# ESP32-P4-LP register map
Vendor: ESPRESSIF SYSTEMS (SHANGHAI) CO., LTD.; Series: ESP32 P-Series; File version: 3
CPU: RV32IMAC r0p0, little endian, no MPU, no FPU, 0 interrupt priority bits
Address unit: 32 bits
Registers are 32-bit, read-write, reset 0x0 unless marked. A register's access mark holds for its fields unless they carry their own. Offsets are from the block's base; [hi:lo] are bit positions; {n}, {i} and the like mark numbered series.

## LP_SPI
Base 0x50123000
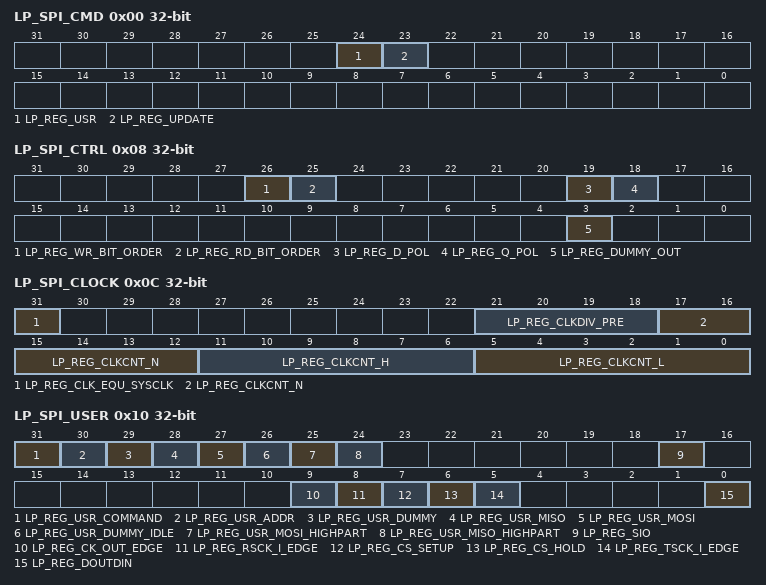
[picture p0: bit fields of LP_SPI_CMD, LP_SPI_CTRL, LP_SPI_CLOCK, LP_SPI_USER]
0x00 LP_SPI_CMD access per field — Command control register
  [24] LP_REG_USR rw — User define command enable. An operation will be triggered when the bit is set. The bit will be cleared once the operation done.1: enable 0: disable. Can not be changed by CONF_buf.
  [23] LP_REG_UPDATE wo — Set this bit to synchronize SPI registers from APB clock domain into SPI module clock domain, which is only used in SPI master mode.
0x04 LP_SPI_ADDR — Address value register
  [31:0] LP_REG_USR_ADDR_VALUE — Address to slave. Can be configured in CONF state.
0x08 LP_SPI_CTRL — SPI control register
  [26] LP_REG_WR_BIT_ORDER — In command address write-data (MOSI) phases 1: LSB firs 0: MSB first. Can be configured in CONF state.
  [25] LP_REG_RD_BIT_ORDER — In read-data (MISO) phase 1: LSB first 0: MSB first. Can be configured in CONF state.
  [19] LP_REG_D_POL — The bit is used to set MOSI line polarity, 1: high 0, low. Can be configured in CONF state.
  [18] LP_REG_Q_POL — The bit is used to set MISO line polarity, 1: high 0, low. Can be configured in CONF state.
  [3] LP_REG_DUMMY_OUT — In the dummy phase the signal level of spi is output by the spi controller. Can be configured in CONF state.
0x0C LP_SPI_CLOCK — SPI clock control register
  [31] LP_REG_CLK_EQU_SYSCLK — In the master mode 1: spi_clk is equal to system 0: spi_clk is divided from system clock. Can be configured in CONF state.
  [21:18] LP_REG_CLKDIV_PRE — In the master mode it is pre-divider of spi_clk. Can be configured in CONF state.
  [17:12] LP_REG_CLKCNT_N — In the master mode it is the divider of spi_clk. So spi_clk frequency is system/(spi_clkdiv_pre+1)/(spi_clkcnt_N+1). Can be configured in CONF state.
  [11:6] LP_REG_CLKCNT_H — In the master mode it must be floor((spi_clkcnt_N+1)/2-1). In the slave mode it must be 0. Can be configured in CONF state.
  [5:0] LP_REG_CLKCNT_L — In the master mode it must be equal to spi_clkcnt_N. In the slave mode it must be 0. Can be configured in CONF state.
0x10 LP_SPI_USER — SPI USER control register
  [31] LP_REG_USR_COMMAND — This bit enable the command phase of an operation. Can be configured in CONF state.
  [30] LP_REG_USR_ADDR — This bit enable the address phase of an operation. Can be configured in CONF state.
  [29] LP_REG_USR_DUMMY — This bit enable the dummy phase of an operation. Can be configured in CONF state.
  [28] LP_REG_USR_MISO — This bit enable the read-data phase of an operation. Can be configured in CONF state.
  [27] LP_REG_USR_MOSI — This bit enable the write-data phase of an operation. Can be configured in CONF state.
  [26] LP_REG_USR_DUMMY_IDLE — spi clock is disable in dummy phase when the bit is enable. Can be configured in CONF state.
  [25] LP_REG_USR_MOSI_HIGHPART — write-data phase only access to high-part of the buffer spi_w8~spi_w15. 1: enable 0: disable. Can be configured in CONF state.
  [24] LP_REG_USR_MISO_HIGHPART — read-data phase only access to high-part of the buffer spi_w8~spi_w15. 1: enable 0: disable. Can be configured in CONF state.
  [17] LP_REG_SIO — Set the bit to enable 3-line half duplex communication mosi and miso signals share the same pin. 1: enable 0: disable. Can be configured in CONF state.
  [9] LP_REG_CK_OUT_EDGE — the bit combined with spi_mosi_delay_mode bits to set mosi signal delay mode. Can be configured in CONF state.
  [8] LP_REG_RSCK_I_EDGE — In the slave mode, this bit can be used to change the polarity of rsck. 0: rsck = !spi_ck_i. 1:rsck = spi_ck_i.
  [7] LP_REG_CS_SETUP — spi cs is enable when spi is in prepare phase. 1: enable 0: disable. Can be configured in CONF state.
  [6] LP_REG_CS_HOLD — spi cs keep low when spi is in done phase. 1: enable 0: disable. Can be configured in CONF state.
  [5] LP_REG_TSCK_I_EDGE — In the slave mode, this bit can be used to change the polarity of tsck. 0: tsck = spi_ck_i. 1:tsck = !spi_ck_i.
  [0] LP_REG_DOUTDIN — Set the bit to enable full duplex communication. 1: enable 0: disable. Can be configured in CONF state.
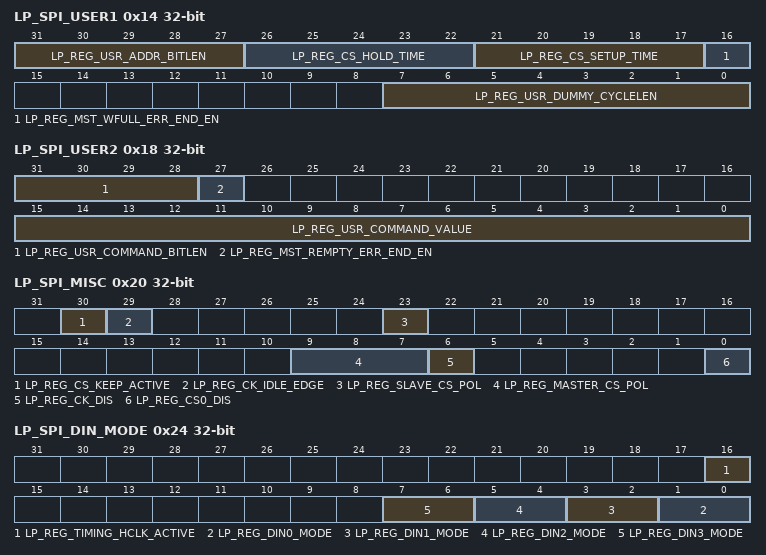
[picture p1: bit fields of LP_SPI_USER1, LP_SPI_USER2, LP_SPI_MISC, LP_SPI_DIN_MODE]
0x14 LP_SPI_USER1 — SPI USER control register 1
  [31:27] LP_REG_USR_ADDR_BITLEN — The length in bits of address phase. The register value shall be (bit_num-1). Can be configured in CONF state.
  [26:22] LP_REG_CS_HOLD_TIME — delay cycles of cs pin by spi clock this bits are combined with spi_cs_hold bit. Can be configured in CONF state.
  [21:17] LP_REG_CS_SETUP_TIME — (cycles+1) of prepare phase by spi clock this bits are combined with spi_cs_setup bit. Can be configured in CONF state.
  [16] LP_REG_MST_WFULL_ERR_END_EN — 1: SPI transfer is ended when SPI RX AFIFO wfull error is valid in GP-SPI master FD/HD-mode. 0: SPI transfer is not ended when SPI RX AFIFO wfull error is valid in GP-SPI master FD/HD-mode.
  [7:0] LP_REG_USR_DUMMY_CYCLELEN — The length in spi_clk cycles of dummy phase. The register value shall be (cycle_num-1). Can be configured in CONF state.
0x18 LP_SPI_USER2 — SPI USER control register 2
  [31:28] LP_REG_USR_COMMAND_BITLEN — The length in bits of command phase. The register value shall be (bit_num-1). Can be configured in CONF state.
  [27] LP_REG_MST_REMPTY_ERR_END_EN — 1: SPI transfer is ended when SPI TX AFIFO read empty error is valid in GP-SPI master FD/HD-mode. 0: SPI transfer is not ended when SPI TX AFIFO read empty error is valid in GP-SPI master FD/HD-mode.
  [15:0] LP_REG_USR_COMMAND_VALUE — The value of command. Can be configured in CONF state.
0x1C LP_SPI_MS_DLEN — SPI data bit length control register
  [17:0] LP_REG_MS_DATA_BITLEN — The value of these bits is the configured SPI transmission data bit length in master mode DMA controlled transfer or CPU controlled transfer. The value is also the configured bit length in slave mode DMA RX controlled transfer. The register value shall be (bit_num-1). Can be configured in CONF state.
0x20 LP_SPI_MISC — SPI misc register
  [30] LP_REG_CS_KEEP_ACTIVE — spi cs line keep low when the bit is set. Can be configured in CONF state.
  [29] LP_REG_CK_IDLE_EDGE — 1: spi clk line is high when idle 0: spi clk line is low when idle. Can be configured in CONF state.
  [23] LP_REG_SLAVE_CS_POL — spi slave input cs polarity select. 1: inv 0: not change. Can be configured in CONF state.
  [9:7] LP_REG_MASTER_CS_POL — In the master mode the bits are the polarity of spi cs line, the value is equivalent to spi_cs ^ spi_master_cs_pol. Can be configured in CONF state.
  [6] LP_REG_CK_DIS — 1: spi clk out disable, 0: spi clk out enable. Can be configured in CONF state.
  [0] LP_REG_CS0_DIS — SPI CS$n pin enable, 1: disable CS$n, 0: spi_cs$n signal is from/to CS$n pin. Can be configured in CONF state.
0x24 LP_SPI_DIN_MODE — SPI input delay mode configuration
  [16] LP_REG_TIMING_HCLK_ACTIVE — 1:enable hclk in SPI input timing module. 0: disable it. Can be configured in CONF state.
  [2n+1:2n] LP_REG_DIN{n}_MODE (n=0..3) — the input signals are delayed by SPI module clock cycles, 0: input without delayed, 1: input with the posedge of clk_apb,2 input with the negedge of clk_apb, 3: input with the spi_clk. Can be configured in CONF state.
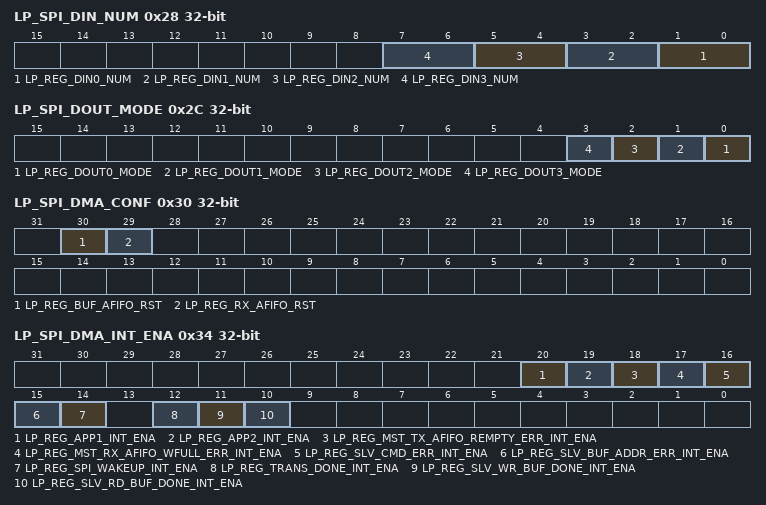
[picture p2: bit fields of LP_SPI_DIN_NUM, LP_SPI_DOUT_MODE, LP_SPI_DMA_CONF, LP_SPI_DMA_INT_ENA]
0x28 LP_SPI_DIN_NUM — SPI input delay number configuration
  [2n+1:2n] LP_REG_DIN{n}_NUM (n=0..3) — the input signals are delayed by SPI module clock cycles, 0: delayed by 1 cycle, 1: delayed by 2 cycles,... Can be configured in CONF state.
0x2C LP_SPI_DOUT_MODE — SPI output delay mode configuration
  [n] LP_REG_DOUT{n}_MODE (n=0..3) — The output signal $n is delayed by the SPI module clock, 0: output without delayed, 1: output delay for a SPI module clock cycle at its negative edge. Can be configured in CONF state.
0x30 LP_SPI_DMA_CONF wo — SPI DMA control register
  [30] LP_REG_BUF_AFIFO_RST — Set this bit to reset BUF TX AFIFO, which is used send data out in SPI slave CPU controlled mode transfer and master mode transfer.
  [29] LP_REG_RX_AFIFO_RST — Set this bit to reset RX AFIFO, which is used to receive data in SPI master and slave mode transfer.
0x34 LP_SPI_DMA_INT_ENA — SPI DMA interrupt enable register
  [20] LP_REG_APP1_INT_ENA — The enable bit for SPI_APP1_INT interrupt.
  [19] LP_REG_APP2_INT_ENA — The enable bit for SPI_APP2_INT interrupt.
  [18] LP_REG_MST_TX_AFIFO_REMPTY_ERR_INT_ENA — The enable bit for SPI_MST_TX_AFIFO_REMPTY_ERR_INT interrupt.
  [17] LP_REG_MST_RX_AFIFO_WFULL_ERR_INT_ENA — The enable bit for SPI_MST_RX_AFIFO_WFULL_ERR_INT interrupt.
  [16] LP_REG_SLV_CMD_ERR_INT_ENA — The enable bit for SPI_SLV_CMD_ERR_INT interrupt.
  [15] LP_REG_SLV_BUF_ADDR_ERR_INT_ENA — The enable bit for SPI_SLV_BUF_ADDR_ERR_INT interrupt.
  [14] LP_REG_SPI_WAKEUP_INT_ENA — The enable bit for SPI_WAKEUP_INT interrupt
  [12] LP_REG_TRANS_DONE_INT_ENA — The enable bit for SPI_TRANS_DONE_INT interrupt.
  [11] LP_REG_SLV_WR_BUF_DONE_INT_ENA — The enable bit for SPI_SLV_WR_BUF_DONE_INT interrupt.
  [10] LP_REG_SLV_RD_BUF_DONE_INT_ENA — The enable bit for SPI_SLV_RD_BUF_DONE_INT interrupt.
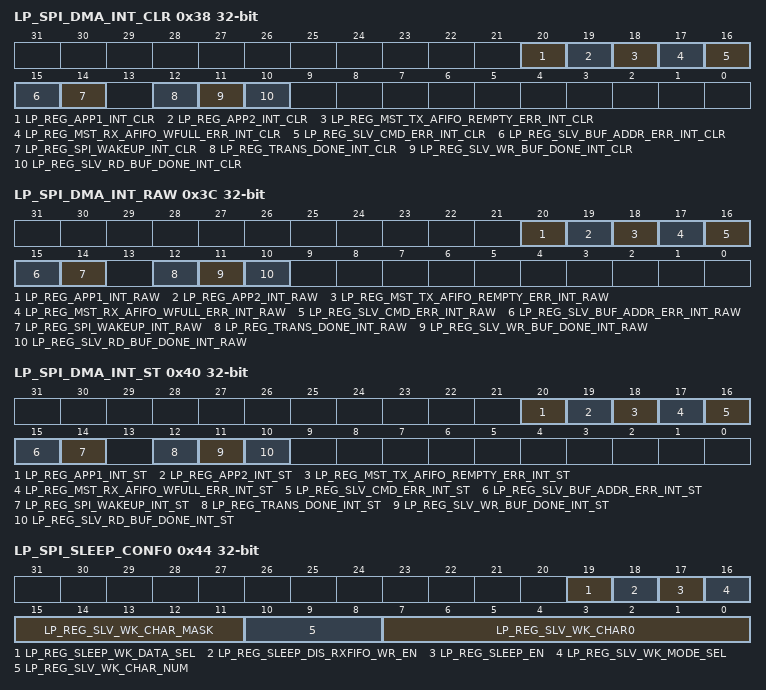
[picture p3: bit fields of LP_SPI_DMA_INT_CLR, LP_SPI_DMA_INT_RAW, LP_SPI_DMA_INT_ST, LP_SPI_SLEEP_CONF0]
0x38 LP_SPI_DMA_INT_CLR wo — SPI DMA interrupt clear register
  [20] LP_REG_APP1_INT_CLR — The clear bit for SPI_APP1_INT interrupt.
  [19] LP_REG_APP2_INT_CLR — The clear bit for SPI_APP2_INT interrupt.
  [18] LP_REG_MST_TX_AFIFO_REMPTY_ERR_INT_CLR — The clear bit for SPI_MST_TX_AFIFO_REMPTY_ERR_INT interrupt.
  [17] LP_REG_MST_RX_AFIFO_WFULL_ERR_INT_CLR — The clear bit for SPI_MST_RX_AFIFO_WFULL_ERR_INT interrupt.
  [16] LP_REG_SLV_CMD_ERR_INT_CLR — The clear bit for SPI_SLV_CMD_ERR_INT interrupt.
  [15] LP_REG_SLV_BUF_ADDR_ERR_INT_CLR — The clear bit for SPI_SLV_BUF_ADDR_ERR_INT interrupt.
  [14] LP_REG_SPI_WAKEUP_INT_CLR — The clear bit for SPI_WAKEUP_INT interrupt
  [12] LP_REG_TRANS_DONE_INT_CLR — The clear bit for SPI_TRANS_DONE_INT interrupt.
  [11] LP_REG_SLV_WR_BUF_DONE_INT_CLR — The clear bit for SPI_SLV_WR_BUF_DONE_INT interrupt.
  [10] LP_REG_SLV_RD_BUF_DONE_INT_CLR — The clear bit for SPI_SLV_RD_BUF_DONE_INT interrupt.
0x3C LP_SPI_DMA_INT_RAW — SPI DMA interrupt raw register
  [20] LP_REG_APP1_INT_RAW — The raw bit for SPI_APP1_INT interrupt. The value is only controlled by application.
  [19] LP_REG_APP2_INT_RAW — The raw bit for SPI_APP2_INT interrupt. The value is only controlled by application.
  [18] LP_REG_MST_TX_AFIFO_REMPTY_ERR_INT_RAW — The raw bit for SPI_MST_TX_AFIFO_REMPTY_ERR_INT interrupt. 1: There is a TX BUF AFIFO read-empty error when SPI outputs data in master mode. 0: Others.
  [17] LP_REG_MST_RX_AFIFO_WFULL_ERR_INT_RAW — The raw bit for SPI_MST_RX_AFIFO_WFULL_ERR_INT interrupt. 1: There is a RX AFIFO write-full error when SPI inputs data in master mode. 0: Others.
  [16] LP_REG_SLV_CMD_ERR_INT_RAW — The raw bit for SPI_SLV_CMD_ERR_INT interrupt. 1: The slave command value in the current SPI slave HD mode transmission is not supported. 0: Others.
  [15] LP_REG_SLV_BUF_ADDR_ERR_INT_RAW — The raw bit for SPI_SLV_BUF_ADDR_ERR_INT interrupt. 1: The accessing data address of the current SPI slave mode CPU controlled FD, Wr_BUF or Rd_BUF transmission is bigger than 63. 0: Others.
  [14] LP_REG_SPI_WAKEUP_INT_RAW — The raw bit for SPI_SPI_WAKEUP_INT interrupt. 1: There is a wake up signal when low power mode. 0: Others.
  [12] LP_REG_TRANS_DONE_INT_RAW — The raw bit for SPI_TRANS_DONE_INT interrupt. 1: SPI master mode transmission is ended. 0: others.
  [11] LP_REG_SLV_WR_BUF_DONE_INT_RAW — The raw bit for SPI_SLV_WR_BUF_DONE_INT interrupt. 1: SPI slave mode Wr_BUF transmission is ended. 0: Others.
  [10] LP_REG_SLV_RD_BUF_DONE_INT_RAW — The raw bit for SPI_SLV_RD_BUF_DONE_INT interrupt. 1: SPI slave mode Rd_BUF transmission is ended. 0: Others.
0x40 LP_SPI_DMA_INT_ST ro — SPI DMA interrupt status register
  [20] LP_REG_APP1_INT_ST — The status bit for SPI_APP1_INT interrupt.
  [19] LP_REG_APP2_INT_ST — The status bit for SPI_APP2_INT interrupt.
  [18] LP_REG_MST_TX_AFIFO_REMPTY_ERR_INT_ST — The status bit for SPI_MST_TX_AFIFO_REMPTY_ERR_INT interrupt.
  [17] LP_REG_MST_RX_AFIFO_WFULL_ERR_INT_ST — The status bit for SPI_MST_RX_AFIFO_WFULL_ERR_INT interrupt.
  [16] LP_REG_SLV_CMD_ERR_INT_ST — The status bit for SPI_SLV_CMD_ERR_INT interrupt.
  [15] LP_REG_SLV_BUF_ADDR_ERR_INT_ST — The status bit for SPI_SLV_BUF_ADDR_ERR_INT interrupt.
  [14] LP_REG_SPI_WAKEUP_INT_ST — reserved
  [12] LP_REG_TRANS_DONE_INT_ST — The status bit for SPI_TRANS_DONE_INT interrupt.
  [11] LP_REG_SLV_WR_BUF_DONE_INT_ST — The status bit for SPI_SLV_WR_BUF_DONE_INT interrupt.
  [10] LP_REG_SLV_RD_BUF_DONE_INT_ST — The status bit for SPI_SLV_RD_BUF_DONE_INT interrupt.
0x44 LP_SPI_SLEEP_CONF0
  [19] LP_REG_SLEEP_WK_DATA_SEL, [18] LP_REG_SLEEP_DIS_RXFIFO_WR_EN, [17] LP_REG_SLEEP_EN, [16] LP_REG_SLV_WK_MODE_SEL, [15:11] LP_REG_SLV_WK_CHAR_MASK, [10:8] LP_REG_SLV_WK_CHAR_NUM, [7:0] LP_REG_SLV_WK_CHAR0
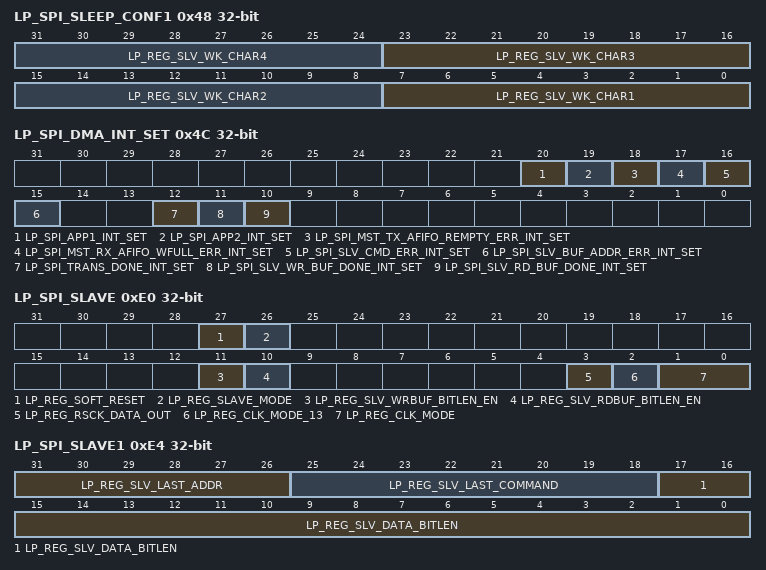
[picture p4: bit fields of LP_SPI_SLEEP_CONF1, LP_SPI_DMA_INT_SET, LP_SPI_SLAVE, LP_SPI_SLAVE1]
0x48 LP_SPI_SLEEP_CONF1
  [8n-1:8n-8] LP_REG_SLV_WK_CHAR{n} (n=1..4)
0x4C LP_SPI_DMA_INT_SET wo — SPI interrupt software set register
  [20] LP_SPI_APP1_INT_SET — The software set bit for SPI_APP1_INT interrupt.
  [19] LP_SPI_APP2_INT_SET — The software set bit for SPI_APP2_INT interrupt.
  [18] LP_SPI_MST_TX_AFIFO_REMPTY_ERR_INT_SET — The software set bit for SPI_MST_TX_AFIFO_REMPTY_ERR_INT interrupt.
  [17] LP_SPI_MST_RX_AFIFO_WFULL_ERR_INT_SET — The software set bit for SPI_MST_RX_AFIFO_WFULL_ERR_INT interrupt.
  [16] LP_SPI_SLV_CMD_ERR_INT_SET — The software set bit for SPI_SLV_CMD_ERR_INT interrupt.
  [15] LP_SPI_SLV_BUF_ADDR_ERR_INT_SET — The software set bit for SPI_SLV_BUF_ADDR_ERR_INT interrupt.
  [12] LP_SPI_TRANS_DONE_INT_SET — The software set bit for SPI_TRANS_DONE_INT interrupt.
  [11] LP_SPI_SLV_WR_BUF_DONE_INT_SET — The software set bit for SPI_SLV_WR_BUF_DONE_INT interrupt.
  [10] LP_SPI_SLV_RD_BUF_DONE_INT_SET — The software set bit for SPI_SLV_RD_BUF_DONE_INT interrupt.
{0x98+4i} LP_SPI_W{i} (i=0..15) — SPI CPU-controlled buffer{i}
  [31:0] LP_REG_BUF{i} — data buffer
0xE0 LP_SPI_SLAVE access per field — SPI slave control register
  [27] LP_REG_SOFT_RESET wo — Software reset enable, reset the spi clock line cs line and data lines. Can be configured in CONF state.
  [26] LP_REG_SLAVE_MODE rw — Set SPI work mode. 1: slave mode 0: master mode.
  [11] LP_REG_SLV_WRBUF_BITLEN_EN rw — 1: SPI_SLV_DATA_BITLEN stores data bit length of master-write-to-slave data length in CPU controlled mode(Wr_BUF). 0: others
  [10] LP_REG_SLV_RDBUF_BITLEN_EN rw — 1: SPI_SLV_DATA_BITLEN stores data bit length of master-read-slave data length in CPU controlled mode(Rd_BUF). 0: others
  [3] LP_REG_RSCK_DATA_OUT rw — It saves half a cycle when tsck is the same as rsck. 1: output data at rsck posedge 0: output data at tsck posedge
  [2] LP_REG_CLK_MODE_13 rw — {CPOL, CPHA},1: support spi clk mode 1 and 3, first edge output data B[0]/B[7]. 0: support spi clk mode 0 and 2, first edge output data B[1]/B[6].
  [1:0] LP_REG_CLK_MODE rw — SPI clock mode bits. 0: SPI clock is off when CS inactive 1: SPI clock is delayed one cycle after CS inactive 2: SPI clock is delayed two cycles after CS inactive 3: SPI clock is always on. Can be configured in CONF state.
0xE4 LP_SPI_SLAVE1 — SPI slave control register 1
  [31:26] LP_REG_SLV_LAST_ADDR — In the slave mode it is the value of address.
  [25:18] LP_REG_SLV_LAST_COMMAND — In the slave mode it is the value of command.
  [17:0] LP_REG_SLV_DATA_BITLEN — The transferred data bit length in SPI slave FD and HD mode.
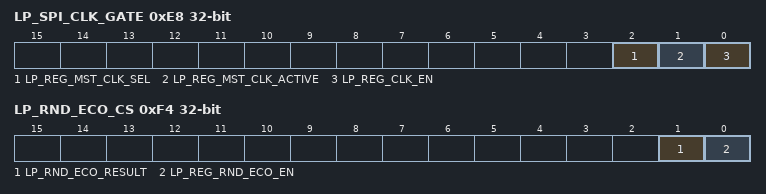
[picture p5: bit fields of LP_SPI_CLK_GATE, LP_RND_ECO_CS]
0xE8 LP_SPI_CLK_GATE — SPI module clock and register clock control
  [2] LP_REG_MST_CLK_SEL — This bit is used to select SPI module clock source in master mode. 1: PLL_CLK_80M. 0: XTAL CLK.
  [1] LP_REG_MST_CLK_ACTIVE — Set this bit to power on the SPI module clock.
  [0] LP_REG_CLK_EN — Set this bit to enable clk gate
0xF0 LP_SPI_DATE — Version control
  [27:0] LP_REG_DATE — SPI register version.
0xF4 LP_RND_ECO_CS access per field
  [1] LP_RND_ECO_RESULT ro, [0] LP_REG_RND_ECO_EN rw
0xF8 LP_RND_ECO_LOW
  [31:0] LP_REG_RND_ECO_LOW
0xFC LP_RND_ECO_HIGH
  [31:0] LP_REG_RND_ECO_HIGH
